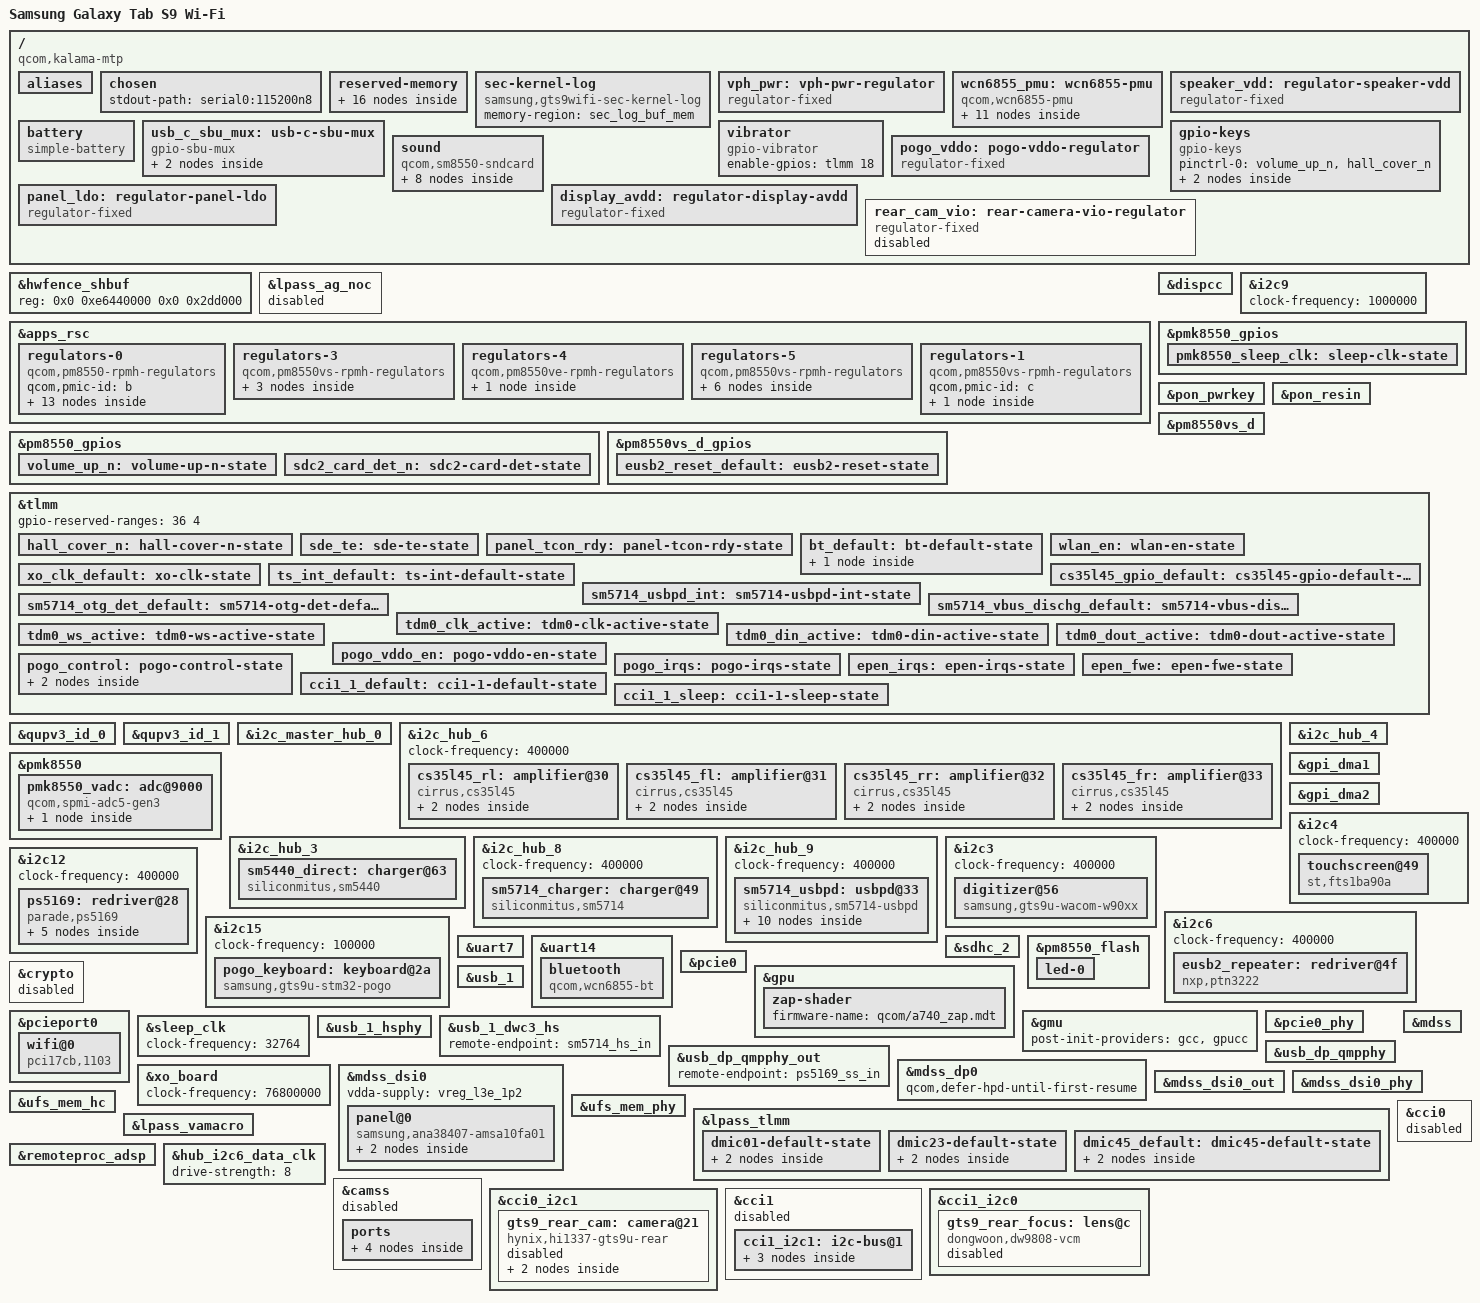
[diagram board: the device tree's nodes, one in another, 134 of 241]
// SPDX-License-Identifier: BSD-3-Clause
/*
 * Initial mainline device tree for the Samsung Galaxy Tab S9 Ultra Wi-Fi
 * (SM-X710, gts9wifi).  Derived from the validated gts9uwifi board; the
 * family shares the SoC, bus topology, amplifiers, charging and pen stack.
 * X710 deltas: AMSA10FA01 panel glass, STM FTS touch (Goodix on some units),
 * WCN6855/QCA6490 WLAN+BT, two HI1337 cameras (described at the end of this
 * file and disabled at boot; gts9wifi_camera enables them on request).
 *
 * Only hardware evidenced by the live downstream tree is enabled here.
 * Native display support remains disabled; Samsung ABL's preserved splash
 * framebuffer is used for the first visual milestone.
 */

/dts-v1/;

#include <dt-bindings/gpio/gpio.h>
#include <dt-bindings/input/input.h>
#include <dt-bindings/iio/qcom,spmi-vadc.h>
#include <dt-bindings/interrupt-controller/irq.h>
#include <dt-bindings/leds/common.h>
#include <dt-bindings/pinctrl/qcom,pmic-gpio.h>
#include <dt-bindings/regulator/qcom,rpmh-regulator.h>
#include <dt-bindings/usb/pd.h>
#include "sm8550.dtsi"
#include "pm8550.dtsi"
#include "pm8550vs.dtsi"
#include "pmk8550.dtsi"

/* Samsung's ADSP/SLPI carveout is larger than the SM8550 reference value. */
/delete-node/ &adspslpi_mem;

/ {
	model = "Samsung Galaxy Tab S9 Wi-Fi";
	/*
	 * The first three strings and the legacy IDs are consumed by Samsung ABL
	 * when it selects the base DTB.  Keep the upstream compatibles as well so
	 * Linux still identifies the actual board and SoC normally.
	 */
	compatible = "qcom,kalama-mtp", "qcom,kalama", "qcom,mtp",
		     "samsung,gts9wifi", "qcom,sm8550";
	qcom,msm-id = <0x218 0x20000 0x207 0x20000
		       0x207 0x10000 0x218 0x10000>;
	/*
	 * Samsung's gts9wifi_eur_open_w00_r04.dts: board-id 04 covers hw_rev 4..0x20;
	 * this unit is rev 6.  The Ultra's trees carry 03.
	 */
	qcom,board-id = <0x10008 0x04>;
	chassis-type = "tablet";

	aliases {
		serial0 = &uart7;
		mmc1 = &sdhc_2;
	};

	chosen {
		stdout-path = "serial0:115200n8";
		/*
		 * The simple-framebuffer is intentionally gone: the native msm
		 * DPU + DSI pipeline (below) owns the panel now.  If the panel
		 * bring-up regresses, recover over SSH (Wi-Fi) or reflash v0.53.
		 */
	};

	reserved-memory {
		/*
		 * Samsung ABL patches the /memory ranges but, without the stock
		 * overlay, does not add the board-only protected carveouts below.
		 * Keep them out of the buddy allocator: touching one of these ranges
		 * can make the secure firmware reset the SoC with a fatal NoC error.
		 */
		kaslr_mem: kaslr@b01ff000 {
			reg = <0x0 0xb01ff000 0x0 0x1000>;
			no-map;
		};

		uh_heap_mem: uh-heap@b0200000 {
			reg = <0x0 0xb0200000 0x0 0x40000>;
			no-map;
		};

		uh_guest_mem: uh-guest@b1000000 {
			reg = <0x0 0xb1000000 0x0 0x3a00000>;
			no-map;
		};

		chipinfo_mem: chipinfo@81cf4000 {
			reg = <0x0 0x81cf4000 0x0 0x1000>;
			no-map;
		};

		sec_xbl_ramdump_mem: sec-xbl-ramdump@a7d00000 {
			reg = <0x0 0xa7d00000 0x0 0x300000>;
			no-map;
		};

		adspslpi_mem: adspslpi@9ea00000 {
			reg = <0x0 0x9ea00000 0x0 0x59b4000>;
			no-map;
		};

		llcc_lpi_mem: llcc-lpi@ff800000 {
			reg = <0x0 0xff800000 0x0 0x600000>;
			no-map;
		};

		/* X910 ABL expects this exact downstream node name and label. */
		splash_region {
			reg = <0x0 0xb8000000 0x0 0x2b00000>;
			label = "cont_splash_region";
			no-map;
		};

		sec_debug_pool_mem: sec-debug-pool@880100000 {
			reg = <0x8 0x80100000 0x0 0xff000>;
			no-map;
		};

		sec_reset_info_mem: sec-reset-info@8801ff000 {
			reg = <0x8 0x801ff000 0x0 0x1000>;
			no-map;
		};

		/* Shared with Samsung bootloader and recovery for /proc/last_kmsg. */
		sec_log_buf_mem: sec-log@880200000 {
			reg = <0x8 0x80200000 0x0 0x200000>;
		};

		sec_debug_bl_mem: sec-debug-bl@880400000 {
			reg = <0x8 0x80400000 0x0 0x500000>;
			no-map;
		};

		/*
		 * Samsung's own kernel keeps its pstore pmsg log in this carve-out
		 * (samsung,pstore_pmsg in the stock gts9wifi overlay) so that it
		 * survives a reset.  Nothing else uses it here: make it the ramoops
		 * backend.  The previous boot's console and its oops/panic records
		 * then appear under /sys/fs/pstore, even when the hang left no
		 * journal.  Write-combined (mem-type 0), so writes reach DDR before
		 * a reset; ECC flags a record the reset corrupted.
		 *
		 * Checked on the X710 (2026-11-07): the console record survived
		 * every warm reboot and watchdog reset, and nothing suggests the
		 * bootloader overruns sec-debug-bl (which ends exactly here) into
		 * it: zone 0 (the first dmesg record) read back uncorrectable only
		 * on the two boots that followed a TWRP session, consistent with
		 * Samsung's kernel there writing its sec_pmsg ring from offset 0.
		 * The console zone is the second MiB and was intact even then.
		 * The few corrected header bytes reported in six of the eight
		 * dmesg zones at every boot first appeared across one clean reboot
		 * after Stage 1 had zapped every zone.  They persist because
		 * ramoops rewrites a dmesg zone's header only when it stores an
		 * oops or panic there, and they creep up a byte at a time (2 2 5 2
		 * 3 3 -> 3 2 5 2 3 4 over that night's five boot-loop boots):
		 * scattered bytes accumulating in untouched headers, not the
		 * contiguous overwrite from offset 0 an overrun would leave.  ECC
		 * corrects up to 8 bytes per header; a zone past that reads back
		 * uncorrectable and is normally zapped and rewritten.  No reason
		 * to move or shrink the region.  systemd-pstore's copies are kept
		 * per boot by ubuntu-gts9u-pstore-archive.service (the device
		 * package).
		 */
		sec_pmsg_mem: sec-pmsg@880900000 {
			compatible = "ramoops";
			reg = <0x8 0x80900000 0x0 0x200000>;
			no-map;
			record-size = <0x20000>;
			console-size = <0x100000>;
			ecc-size = <16>;
		};

		google_debug_kinfo_mem: google-debug-kinfo@880b00000 {
			reg = <0x8 0x80b00000 0x0 0x1000>;
			no-map;
		};

		hdm_mem: hdm@880b01000 {
			reg = <0x8 0x80b01000 0x0 0x1000>;
			no-map;
		};

		sec_qcom_rdx_mem: sec-qcom-rdx@880c00000 {
			reg = <0x8 0x80c00000 0x0 0xad00000>;
			no-map;
		};
	};

	sec-kernel-log {
		compatible = "samsung,gts9wifi-sec-kernel-log", "samsung,gts9uwifi-sec-kernel-log";
		memory-region = <&sec_log_buf_mem>;
	};

	/* Mainline WCN7850 power sequencer input, as on the SM8550 QRD. */
	vph_pwr: vph-pwr-regulator {
		compatible = "regulator-fixed";
		regulator-name = "vph_pwr";
		regulator-min-microvolt = <3700000>;
		regulator-max-microvolt = <3700000>;
		regulator-always-on;
		regulator-boot-on;
	};

	wcn6855_pmu: wcn6855-pmu {
		compatible = "qcom,wcn6855-pmu";
		pinctrl-names = "default";
		pinctrl-0 = <&wlan_en>, <&bt_default>, <&xo_clk_default>,
			    <&pmk8550_sleep_clk>;

		/*
		 * Stock gts9wifi cnss-qca6490 and bt_qca6490 nodes: wlan-en 80,
		 * bt-en 81, sw-ctrl 82 and xo-clk 204, the SM8450 HDK WCN6855
		 * wiring.  Unlike the X910's WCN7850 this part needs XO_CLK held
		 * high across BT_EN/WLAN_EN assertion; without it neither radio
		 * leaves reset (hci0 "Reading QCA version information failed
		 * (-110)", PCIe LTSSM parked in Detect, "Device not found").
		 */
		wlan-enable-gpios = <&tlmm 80 GPIO_ACTIVE_HIGH>;
		bt-enable-gpios = <&tlmm 81 GPIO_ACTIVE_HIGH>;
		swctrl-gpios = <&tlmm 82 GPIO_ACTIVE_HIGH>;
		xo-clk-gpios = <&tlmm 204 GPIO_ACTIVE_HIGH>;

		/*
		 * Stock cnss2 sends this exact qcom,pdc_init_table (gts9wifi r04
		 * qcom,cnss-qca6490 node) to the AOP through the QMP mailbox
		 * before the first WLAN power-on.  It programs the RF rail
		 * levels the AOP applies when the QCA6490 PMU raises its power
		 * requests over the PDC; without it the PMU handshake never
		 * completes on the X910 and both radios stay in reset.
		 */
		qcom,qmp = <&aoss_qmp>;
		qcom,wlan-pdc-init =
			"{class: wlan_pdc, ss: rf, res: s4e.v, upval: 966}",
			"{class: wlan_pdc, ss: rf, res: s4e.v, dwnval: 615}",
			"{class: wlan_pdc, ss: rf, res: s4g.v, upval: 1350}",
			"{class: wlan_pdc, ss: rf, res: s4g.v, dwnval: 945}",
			"{class: wlan_pdc, ss: rf, res: s6g.v, upval: 1900}",
			"{class: wlan_pdc, ss: rf, res: s6g.v, dwnval: 1825}",
			"{class: wlan_pdc, ss: rf, res: s2g.m, enable: 1}",
			"{class: wlan_pdc, ss: rf, res: s2g.v, enable: 1}",
			"{class: wlan_pdc, ss: rf, res: s2g.v, upval: 1012}",
			"{class: wlan_pdc, ss: rf, res: s2g.v, dwnval: 800}",
			"{class: wlan_pdc, ss: bb, res: pdc, enable: 0}";

		/*
		 * Rails as voted by the stock gts9wifi radio nodes: L15B io,
		 * S2G WLAN_AON (1.012 V), S4E dig/rfa0p8 (0.966 V), S4G 1.35 V
		 * and S6G 1.9 V, plus the S5G 0.966 V PMU core vote the Fedora
		 * and pmOS X710 trees carry (stock "vdd-wlan" has no phandle).
		 */
		vddio-supply = <&vreg_l15b_1p8>;
		vddaon-supply = <&vreg_s2g_1p012>;
		vddpmu-supply = <&vreg_s5g_0p968>;
		vddpmumx-supply = <&vreg_s5g_0p968>;
		vddpmucx-supply = <&vreg_s5g_0p968>;
		vddrfa0p95-supply = <&vreg_s4e_0p968>;
		vddrfa1p3-supply = <&vreg_s4g_1p352>;
		vddrfa1p9-supply = <&vreg_s6g_1p904>;
		vddpcie1p3-supply = <&vreg_s4g_1p352>;
		vddpcie1p9-supply = <&vreg_s6g_1p904>;

		regulators {
			vreg_pmu_rfa_cmn: ldo0 {
				regulator-name = "vreg_pmu_rfa_cmn_0p8";
			};

			vreg_pmu_aon_0p8: ldo1 {
				regulator-name = "vreg_pmu_aon_0p8";
			};

			vreg_pmu_wlcx_0p8: ldo2 {
				regulator-name = "vreg_pmu_wlcx_0p8";
			};

			vreg_pmu_wlmx_0p8: ldo3 {
				regulator-name = "vreg_pmu_wlmx_0p8";
			};

			vreg_pmu_btcmx_0p8: ldo4 {
				regulator-name = "vreg_pmu_btcmx_0p8";
			};

			vreg_pmu_pcie_1p8: ldo5 {
				regulator-name = "vreg_pmu_pcie_1p8";
			};

			vreg_pmu_pcie_0p9: ldo6 {
				regulator-name = "vreg_pmu_pcie_0p9";
			};

			vreg_pmu_rfa_0p8: ldo7 {
				regulator-name = "vreg_pmu_rfa_0p8";
			};

			vreg_pmu_rfa_1p2: ldo8 {
				regulator-name = "vreg_pmu_rfa_1p2";
			};

			vreg_pmu_rfa_1p7: ldo9 {
				regulator-name = "vreg_pmu_rfa_1p7";
			};
		};
	};

	/*
	 * The four CS35L45 speaker amplifiers share one board power switch.
	 * Samsung's stock overlay calls this a dummy regulator, but GPIO19 is
	 * the real active-high enable and the rail is intentionally always on.
	 */
	speaker_vdd: regulator-speaker-vdd {
		compatible = "regulator-fixed";
		regulator-name = "speaker_vdd";
		gpio = <&tlmm 19 GPIO_ACTIVE_HIGH>;
		enable-active-high;
		regulator-always-on;
		regulator-boot-on;
	};

	/*
	 * EB-BX916ABY.  The design figures come from Samsung's own sec-battery
	 * node (battery,battery_full_capacity = 9800 mAh, chg_float_voltage =
	 * 4440 mV), not from the marketing "11200 mAh" figure.  The fuel gauge
	 * reports state of charge itself, so these only feed the time-remaining
	 * estimate.
	 */
	battery: battery {
		compatible = "simple-battery";
		charge-full-design-microamp-hours = <9800000>;
		voltage-max-design-microvolt = <4440000>;
		voltage-min-design-microvolt = <3400000>;
	};

	/*
	 * The stock DP driver drives these two discrete AUX-path controls:
	 * GPIO183 is active-low enable and GPIO180 follows cable orientation.
	 * The generic mainline SBU mux maps those exact semantics onto Type-C.
	 */
	usb_c_sbu_mux: usb-c-sbu-mux {
		compatible = "gpio-sbu-mux";
		enable-gpios = <&tlmm 183 GPIO_ACTIVE_LOW>;
		select-gpios = <&tlmm 180 GPIO_ACTIVE_HIGH>;
		mode-switch;
		orientation-switch;

		port {
			usb_c_sbu_mux_in: endpoint {
				remote-endpoint = <&sm5714_sbu_out>;
			};
		};
	};

	/*
	 * Stock dc_vibrator: Samsung drives the coin motor from TLMM GPIO18.  The
	 * r04 overlay wires it exactly as the Ultra's does -- COINDC, gpio_en
	 * TLMM 18 active high (their "mot_ldo_en"), no regulator -- so the
	 * Ultra's node applies unchanged.  Tab Companion's keyboard and
	 * notification haptics find it by its input name, gpio-vibrator.
	 */
	vibrator {
		compatible = "gpio-vibrator";
		enable-gpios = <&tlmm 18 GPIO_ACTIVE_HIGH>;
	};

	gpio-keys {
		compatible = "gpio-keys";
		pinctrl-names = "default";
		pinctrl-0 = <&volume_up_n>, <&hall_cover_n>;

		key-volume-up {
			label = "Volume Up";
			linux,code = <KEY_VOLUMEUP>;
			gpios = <&pm8550_gpios 6 GPIO_ACTIVE_LOW>;
			debounce-interval = <15>;
			linux,can-disable;
			wakeup-source;
		};

		/*
		 * Samsung's stock hall_ic node identifies the book-cover magnet
		 * on TLMM GPIO107, active low, with a 50 ms debounce.  Report the
		 * standard SW_LID event so logind and GNOME can blank/suspend on
		 * close without a device-specific daemon.
		 */
		switch-lid {
			label = "Book Cover";
			linux,input-type = <EV_SW>;
			linux,code = <SW_LID>;
			gpios = <&tlmm 107 GPIO_ACTIVE_LOW>;
			debounce-interval = <50>;
			wakeup-source;
		};
	};

	/*
	 * Unlike the SM8550 QRD, the X710 has no WSA884x speaker path and no
	 * WCD938x. Its four CS35L45 amplifiers consume PRIMARY_MI2S_RX over
	 * TLMM126..129. Keep the first card deliberately small: one playback
	 * backend plus the native VA-macro DMIC capture backend.
	 */
	sound {
		compatible = "qcom,sm8550-sndcard", "qcom,sm8450-sndcard";
		model = "Samsung-Galaxy-Tab-S9";
		pinctrl-names = "default";
		pinctrl-0 = <&tdm0_clk_active>, <&tdm0_ws_active>,
			    <&tdm0_din_active>, <&tdm0_dout_active>;

		speaker-playback-dai-link {
			link-name = "CS35L45 Speaker Playback";

			cpu {
				sound-dai = <&q6apmbedai PRIMARY_MI2S_RX>;
			};

			codec {
				sound-dai = <&cs35l45_fl 0>, <&cs35l45_fr 0>,
					    <&cs35l45_rl 0>, <&cs35l45_rr 0>;
			};

			platform {
				sound-dai = <&q6apm>;
			};
		};

		va-capture-dai-link {
			link-name = "Internal DMIC Capture";

			cpu {
				/*
				 * The VA macro has its own LPASS DMA lane: its
				 * capture lands on VA_CODEC_DMA_TX_0, not on the
				 * TX macro's TX_CODEC_DMA_TX_3 (which is where
				 * the reference boards take their soundwire mics
				 * from, and which this tablet does not have).
				 * Wiring the link to the TX lane leaves the
				 * backend with no data and arecord fails with
				 * -EIO.
				 */
				sound-dai = <&q6apmbedai VA_CODEC_DMA_TX_0>;
			};

			codec {
				sound-dai = <&lpass_vamacro 0>;
			};

			platform {
				sound-dai = <&q6apm>;
			};
		};
	};
};

/* The X910 firmware reserves a slightly larger HW-fence window than MTP. */
&hwfence_shbuf {
	reg = <0x0 0xe6440000 0x0 0x2dd000>;
};

/*
 * The v0.5 video ends after the two preceding LPASS NOC providers probe and
 * before this provider can return.  Audio is out of scope for milestone 1;
 * keep the unsafe access quiescent until its board-specific power sequence is
 * understood.
 */
&lpass_ag_noc {
	status = "disabled";
};

&apps_rsc {
	/* PM8550B: only the two external-SD rails needed for milestone 1. */
	regulators-0 {
		compatible = "qcom,pm8550-rpmh-regulators";
		qcom,pmic-id = "b";

		/*
		 * Sensor VDD. Samsung's remoteproc-adsp node votes PM8550B L1 at
		 * 1.8 V as sensor_vdd while the sensors protection domain runs.
		 * Mainline qcom_q6v5_pas only manages cx/px supplies, so keep the
		 * exact stock rail enabled until generic auxiliary-supply handling
		 * exists in that driver. On the X910, omitting both sensor rails
		 * correlates with the sensors PD watchdog during SSC bring-up.
		 */
		vreg_l1b_1p8: ldo1 {
			regulator-name = "vreg_l1b_1p8";
			regulator-min-microvolt = <1800000>;
			regulator-max-microvolt = <1800000>;
			regulator-initial-mode = <RPMH_REGULATOR_MODE_HPM>;
			regulator-always-on;
		};

		/* NXP PTN3222 eUSB2 3.1 V rail, exact X910 stock voltage. */
		vreg_l5b_3p104: ldo5 {
			regulator-name = "vreg_l5b_3p104";
			regulator-min-microvolt = <3104000>;
			regulator-max-microvolt = <3104000>;
			regulator-initial-mode = <RPMH_REGULATOR_MODE_HPM>;
			regulator-allow-set-load;
			regulator-allowed-modes = <RPMH_REGULATOR_MODE_LPM
						   RPMH_REGULATOR_MODE_HPM>;
		};

		vreg_l8b_1p8: ldo8 {
			regulator-name = "vreg_l8b_1p8";
			regulator-min-microvolt = <1800000>;
			regulator-max-microvolt = <3000000>;
			regulator-initial-mode = <RPMH_REGULATOR_MODE_HPM>;
		};

		vreg_l9b_2p9: ldo9 {
			regulator-name = "vreg_l9b_2p9";
			regulator-min-microvolt = <2960000>;
			regulator-max-microvolt = <3000000>;
			regulator-initial-mode = <RPMH_REGULATOR_MODE_HPM>;
		};

		/*
		 * Digital microphone bias.  Samsung wires the VA macro's
		 * va-vdd-micb to this LDO (their pm_humu_l10, resource ldob10) at
		 * 1.8 V; without it the driver falls back to a dummy regulator and
		 * the DMICs stay unpowered, so capture returns silence.
		 */
		vreg_l10b_1p8: ldo10 {
			regulator-name = "vreg_l10b_1p8";
			regulator-min-microvolt = <1800000>;
			regulator-max-microvolt = <1800000>;
			regulator-initial-mode = <RPMH_REGULATOR_MODE_HPM>;
			/*
			 * The VA macro declares vdd-micb as a DAPM regulator
			 * supply but never puts it in a route, so the widget is
			 * never powered and the rail stays off even with a
			 * capture running - the microphones then sit unpowered
			 * and return digital silence.  Until the driver wires
			 * that supply into the DMIC paths, keep the rail up.
			 */
			regulator-always-on;
		};

		/* Stock pm_humu_l11: shared 1.1 V camera/display digital rail. */
		vreg_l11b_1p2: ldo11 {
			regulator-name = "vreg_l11b_1p2";
			/*
			 * Panel VDD.  The gts9wifi stock tree leaves L11B at its
			 * 1.200 V base vote (the X910 overlay lowers it to 1.100 V) and
			 * the pmOS tree drives this glass at 1.2 V as well.
			 */
			regulator-min-microvolt = <1200000>;
			regulator-max-microvolt = <1200000>;
			regulator-initial-mode = <RPMH_REGULATOR_MODE_HPM>;
		};

		vreg_l12b_1p8: ldo12 {
			regulator-name = "vreg_l12b_1p8";
			regulator-min-microvolt = <1800000>;
			regulator-max-microvolt = <1800000>;
			regulator-initial-mode = <RPMH_REGULATOR_MODE_HPM>;
		};

		/* Display panel VCI (3.0 V analog). */
		vreg_l13b_3p0: ldo13 {
			regulator-name = "vreg_l13b_3p0";
			regulator-min-microvolt = <3000000>;
			regulator-max-microvolt = <3000000>;
			regulator-initial-mode = <RPMH_REGULATOR_MODE_HPM>;
		};

		vreg_l14b_3p2: ldo14 {
			regulator-name = "vreg_l14b_3p2";
			regulator-min-microvolt = <3200000>;
			regulator-max-microvolt = <3200000>;
			regulator-initial-mode = <RPMH_REGULATOR_MODE_HPM>;
		};

		/* NXP PTN3222 eUSB2 1.8 V rail. */
		vreg_l15b_1p8: ldo15 {
			regulator-name = "vreg_l15b_1p8";
			regulator-min-microvolt = <1800000>;
			regulator-max-microvolt = <1800000>;
			regulator-initial-mode = <RPMH_REGULATOR_MODE_HPM>;
			regulator-allow-set-load;
			regulator-allowed-modes = <RPMH_REGULATOR_MODE_LPM
						   RPMH_REGULATOR_MODE_HPM>;
		};

		/*
		 * Sensor VDDIO. The stock ADSP node requests PM8550B L16 at
		 * 3.0 V (sensor_vddio-uV-uA = <3000000 0>); see L1 above for why
		 * this is temporarily an always-on board rail.
		 */
		vreg_l16b_3p0: ldo16 {
			regulator-name = "vreg_l16b_3p0";
			regulator-min-microvolt = <3000000>;
			regulator-max-microvolt = <3000000>;
			regulator-initial-mode = <RPMH_REGULATOR_MODE_HPM>;
			regulator-always-on;
		};

		/* Internal UFS VCC (memory core). */
		vreg_l17b_2p5: ldo17 {
			regulator-name = "vreg_l17b_2p5";
			regulator-min-microvolt = <2504000>;
			regulator-max-microvolt = <2504000>;
			regulator-initial-mode = <RPMH_REGULATOR_MODE_HPM>;
			regulator-allow-set-load;
			regulator-allowed-modes = <RPMH_REGULATOR_MODE_LPM
						   RPMH_REGULATOR_MODE_HPM>;
		};
	};

	/* PM8550VS-E: rails consumed by the primary USB2 PHY. */
	regulators-3 {
		compatible = "qcom,pm8550vs-rpmh-regulators";
		qcom,pmic-id = "e";
		vdd-s4-supply = <&vph_pwr>;
		vdd-s5-supply = <&vph_pwr>;

		vreg_s4e_0p968: smps4 {
			regulator-name = "vreg_s4e_0p968";
			/*
			 * The stock gts9wifi bt/cnss nodes vote 0.966 V here (the
			 * X910 asks 0.950 V); FTSMPS525 rounds up in 4 mV steps.
			 */
			regulator-min-microvolt = <968000>;
			regulator-max-microvolt = <968000>;
			regulator-initial-mode = <RPMH_REGULATOR_MODE_HPM>;
		};

		vreg_l1e_0p88: ldo1 {
			regulator-name = "vreg_l1e_0p88";
			regulator-min-microvolt = <880000>;
			regulator-max-microvolt = <880000>;
			regulator-initial-mode = <RPMH_REGULATOR_MODE_HPM>;
		};

		vreg_l3e_1p2: ldo3 {
			regulator-name = "vreg_l3e_1p2";
			regulator-min-microvolt = <1200000>;
			regulator-max-microvolt = <1200000>;
			regulator-initial-mode = <RPMH_REGULATOR_MODE_HPM>;
		};
	};

	/* PM8550VE-F: 0.88 V PLL rail for the USB3/DisplayPort combo PHY. */
	regulators-4 {
		compatible = "qcom,pm8550ve-rpmh-regulators";
		qcom,pmic-id = "f";
		vdd-l1-supply = <&vreg_s4e_0p968>;
		vdd-l2-supply = <&vreg_s4e_0p968>;
		vdd-l3-supply = <&vreg_s4e_0p968>;

		vreg_l3f_0p88: ldo3 {
			regulator-name = "vreg_l3f_0p88";
			regulator-min-microvolt = <880000>;
			regulator-max-microvolt = <912000>;
			regulator-initial-mode = <RPMH_REGULATOR_MODE_HPM>;
		};
	};

	/* PM8550VS-G supplies the discrete WCN7850/Kiwi v2 radio PMU. */
	regulators-5 {
		compatible = "qcom,pm8550vs-rpmh-regulators";
		qcom,pmic-id = "g";
		vdd-s1-supply = <&vph_pwr>;
		vdd-s2-supply = <&vph_pwr>;
		vdd-s3-supply = <&vph_pwr>;
		vdd-s4-supply = <&vph_pwr>;
		vdd-s5-supply = <&vph_pwr>;
		vdd-s6-supply = <&vph_pwr>;

		vreg_s2g_1p012: smps2 {
			regulator-name = "vreg_s2g_1p012";
			/* Stock gts9wifi cnss-qca6490 votes 1.012 V for WLAN_AON. */
			regulator-min-microvolt = <1012000>;
			regulator-max-microvolt = <1012000>;
			regulator-initial-mode = <RPMH_REGULATOR_MODE_HPM>;
		};

		vreg_s4g_1p352: smps4 {
			regulator-name = "vreg_s4g_1p352";
			/* Stock asks 1.350 V; FTSMPS525 rounds up in 4 mV steps. */
			regulator-min-microvolt = <1352000>;
			regulator-max-microvolt = <1352000>;
			regulator-initial-mode = <RPMH_REGULATOR_MODE_HPM>;
		};

		vreg_s5g_0p968: smps5 {
			regulator-name = "vreg_s5g_0p968";
			/*
			 * The stock gts9wifi cnss node lists a 0.966 V "vdd-wlan" rail
			 * without an APPS phandle; the Fedora and pmOS X710 trees feed
			 * the PMU core inputs from S5G at this level and bring the
			 * radios up, so keep that vote (FTSMPS525 4 mV steps).
			 */
			regulator-min-microvolt = <968000>;
			regulator-max-microvolt = <968000>;
			regulator-initial-mode = <RPMH_REGULATOR_MODE_HPM>;
		};

		vreg_s6g_1p904: smps6 {
			regulator-name = "vreg_s6g_1p904";
			/* Stock asks 1.900 V; FTSMPS525 rounds up in 8 mV steps. */
			regulator-min-microvolt = <1904000>;
			regulator-max-microvolt = <1904000>;
			regulator-initial-mode = <RPMH_REGULATOR_MODE_HPM>;
		};

		/*
		 * Do not add vdd-l3-supply here.  Mainline SM8550 boards expose
		 * PM8550VS-G LDO3 directly, and the experimental S4G parent used in
		 * v0.20 created a fixed dependency cycle with this provider.
		 */
		vreg_l3g_1p2: ldo3 {
			regulator-name = "vreg_l3g_1p2";
			regulator-min-microvolt = <1200000>;
			regulator-max-microvolt = <1200000>;
			regulator-initial-mode = <RPMH_REGULATOR_MODE_HPM>;
		};

		/* Internal UFS VCCQ (controller I/O). */
		vreg_l1g_1p2: ldo1 {
			regulator-name = "vreg_l1g_1p2";
			regulator-min-microvolt = <1200000>;
			regulator-max-microvolt = <1200000>;
			regulator-initial-mode = <RPMH_REGULATOR_MODE_HPM>;
			regulator-allow-set-load;
			regulator-allowed-modes = <RPMH_REGULATOR_MODE_LPM
						   RPMH_REGULATOR_MODE_HPM>;
		};
	};
};

&dispcc {
	/* Needed for the native display pipeline (mdss/dpu/dsi clocks). */
	status = "okay";
};

&pm8550_gpios {
	volume_up_n: volume-up-n-state {
		pins = "gpio6";
		function = "normal";
		power-source = <1>;
		bias-pull-up;
		input-enable;
	};

	sdc2_card_det_n: sdc2-card-det-state {
		pins = "gpio12";
		function = "normal";
		input-enable;
		output-disable;
		bias-pull-up;
		power-source = <1>; /* 1.8 V */
	};
};

&i2c9 {
	clock-frequency = <1000000>;
	status = "okay";

};

&pmk8550_gpios {
	pmk8550_sleep_clk: sleep-clk-state {
		pins = "gpio3";
		function = "func1";
		input-disable;
		output-enable;
		bias-disable;
		power-source = <0>;
	};
};

&pon_pwrkey {
	status = "okay";
};

&pon_resin {
	linux,code = <KEY_VOLUMEDOWN>;
	/*
	 * Volume Down wakes the tablet like Volume Up and the power key, as
	 * under Android: Samsung's pm8941-pwrkey arms both PMIC keys and its
	 * init writes volkey_wakeup=1.  Mainline leaves resin unarmed.
	 */
	wakeup-source;
	status = "okay";
};

/* Stock X910 connects the NXP repeater reset to PM8550VS-D GPIO4. */
&pm8550vs_d {
	status = "okay";
};

&pm8550vs_d_gpios {
	eusb2_reset_default: eusb2-reset-state {
		pins = "gpio4";
		function = "normal";
		power-source = <1>;
		input-enable;
		output-enable;
		drive-push-pull;
		qcom,drive-strength = <PMIC_GPIO_STRENGTH_MED>;
		bias-disable;
	};
};

&tlmm {
	/* GPIO36..39 are secure/reserved in Samsung's board overlay. */
	gpio-reserved-ranges = <36 4>;

	hall_cover_n: hall-cover-n-state {
		pins = "gpio107";
		function = "gpio";
		drive-strength = <2>;
		input-enable;
		bias-disable;
	};

	/* Panel tear-effect (TE) line routed to the MDP vsync input. */
	sde_te: sde-te-state {
		pins = "gpio86";
		function = "mdp_vsync";
		drive-strength = <2>;
		bias-pull-down;
	};

	/* DDIC TCON_RDY input, as the stock panel_fa01_tcon_rdy_active state. */
	panel_tcon_rdy: panel-tcon-rdy-state {
		pins = "gpio88";
		function = "gpio";
		drive-strength = <2>;
		input-enable;
		bias-disable;
	};

	bt_default: bt-default-state {
		bt-en-pins {
			pins = "gpio81";
			function = "gpio";
			drive-strength = <16>;
			bias-disable;
		};
	};

	wlan_en: wlan-en-state {
		pins = "gpio80";
		function = "gpio";
		drive-strength = <16>;
		bias-pull-up;
	};

	/* WCN6855 XO_CLK: driven high by the PMU sequencer during power-on. */
	xo_clk_default: xo-clk-state {
		pins = "gpio204";
		function = "gpio";
		drive-strength = <16>;
		output-low;
		bias-pull-down;
	};

	/* FTS1BA90A attention line, as the stock fts1ba90a_attn_irq state. */
	ts_int_default: ts-int-default-state {
		pins = "gpio25";
		function = "gpio";
		bias-disable;
	};

	cs35l45_gpio_default: cs35l45-gpio-default-state {
		pins = "gpio14", "gpio42";
		function = "gpio";
		drive-strength = <2>;
		bias-disable;
	};

	sm5714_usbpd_int: sm5714-usbpd-int-state {
		pins = "gpio133";
		function = "gpio";
		drive-strength = <8>;
		input-enable;
		bias-disable;
	};

	sm5714_otg_det_default: sm5714-otg-det-default-state {
		pins = "gpio89";
		function = "gpio";
		drive-strength = <2>;
		output-low;
		bias-disable;
	};

	sm5714_vbus_dischg_default: sm5714-vbus-dischg-default-state {
		pins = "gpio175";
		function = "gpio";
		drive-strength = <2>;
		output-low;
		bias-pull-down;
	};

	tdm0_clk_active: tdm0-clk-active-state {
		pins = "gpio126";
		function = "i2s0_sck";
		drive-strength = <2>;
		bias-disable;
		output-high;
	};

	tdm0_ws_active: tdm0-ws-active-state {
		pins = "gpio129";
		function = "i2s0_ws";
		drive-strength = <2>;
		bias-disable;
		output-high;
	};

	tdm0_din_active: tdm0-din-active-state {
		pins = "gpio127";
		function = "i2s0_data0";
		drive-strength = <2>;
		bias-disable;
	};

	tdm0_dout_active: tdm0-dout-active-state {
		pins = "gpio128";
		function = "i2s0_data1";
		drive-strength = <2>;
		bias-disable;
	};

	pogo_vddo_en: pogo-vddo-en-state {
		pins = "gpio10";
		function = "gpio";
		drive-strength = <2>;
		output-low;
		bias-disable;
	};

	pogo_control: pogo-control-state {
		boot-pins {
			pins = "gpio12";
			function = "gpio";
			drive-strength = <2>;
			output-low;
			bias-disable;
		};

		reset-pins {
			pins = "gpio13";
			function = "gpio";
			drive-strength = <2>;
			output-high;
			bias-disable;
		};
	};

	pogo_irqs: pogo-irqs-state {
		pins = "gpio62", "gpio75";
		function = "gpio";
		drive-strength = <2>;
		input-enable;
		bias-disable;
	};

	/*
	 * S Pen digitiser interrupt lines, as Samsung's r04 epen-int-active and
	 * epen-pdct-active states (and the Ultra's node): gpio154 is the data
	 * interrupt, gpio137 the pen-in-silo detect.  Both are inputs with the
	 * pull disabled.
	 */
	epen_irqs: epen-irqs-state {
		pins = "gpio154", "gpio137";
		function = "gpio";
		drive-strength = <2>;
		input-enable;
		bias-disable;
	};

	/*
	 * The digitiser's flash enable.  High across a power-up starts the
	 * controller's loader (Samsung's boot_addr, 0x09) instead of the
	 * digitiser at 0x56.  Samsung's probe drives it low and keeps it there
	 * (wacom_compulsory_flash_mode(false) in wacom_i2c.c); only its firmware
	 * flasher ever raises it, and this port has none.  Hold it low rather
	 * than leave it at whatever the reset default or ABL left behind.
	 */
	epen_fwe: epen-fwe-state {
		pins = "gpio179";
		function = "gpio";
		drive-strength = <2>;
		output-low;
		bias-disable;
	};
};

&qupv3_id_0 {
	status = "okay";
};

/* UART14 (WCN7850 Bluetooth) is a child of the second QUPv3 wrapper. */
&qupv3_id_1 {
	status = "okay";
};

/*
 * Samsung numbers this I2C18. On mainline it is SE6 of the dedicated QUPv3
 * I2C master hub (0x998000), and all four speaker amplifiers live here.
 */
&i2c_master_hub_0 {
	status = "okay";
};

&i2c_hub_6 {
	/*
	 * 400 kHz, not the 1 MHz the downstream stack uses.  Under mainline the
	 * QUPv3 i2c-master-hub runs its SEs in FIFO/PIO mode (no GPI DMA), and at
	 * 1 MHz Fast-Mode Plus the SE accepts the M_CMD but never drives the bus
	 * (mid-hang: bus idle, both lines high, zero interrupts) - the QUP core
	 * clock available to PIO is not enough for FM+.  Every upstream SM8550
	 * board that puts real devices on the i2c hub runs it at <=400 kHz
	 * (sm8550-hdk/mtp/qrd typec muxes at default, sony-xperia-yodo at 400 kHz);
	 * none run it at 1 MHz.  400 kHz is ample for CS35L45 register access and
	 * DSP firmware download.
	 */
	clock-frequency = <400000>;
	status = "okay";

	cs35l45_rl: amplifier@30 {
		compatible = "cirrus,cs35l45";
		reg = <0x30>;
		#sound-dai-cells = <1>;
		interrupt-parent = <&tlmm>;
		interrupts = <14 IRQ_TYPE_LEVEL_LOW>;
		reset-gpios = <&tlmm 42 GPIO_ACTIVE_HIGH>;
		vdd-a-supply = <&speaker_vdd>;
		vdd-batt-supply = <&speaker_vdd>;
		pinctrl-names = "default";
		pinctrl-0 = <&cs35l45_gpio_default>;
		sound-name-prefix = "Rear Left";
		cirrus,asp-sdout-hiz-ctrl = <3>;

		cirrus,gpio-ctrl1 {
			gpio-ctrl = <2>;
		};

		cirrus,gpio-ctrl2 {
			gpio-ctrl = <2>;
		};
	};

	cs35l45_fl: amplifier@31 {
		compatible = "cirrus,cs35l45";
		reg = <0x31>;
		#sound-dai-cells = <1>;
		interrupt-parent = <&tlmm>;
		interrupts = <14 IRQ_TYPE_LEVEL_LOW>;
		reset-gpios = <&tlmm 42 GPIO_ACTIVE_HIGH>;
		vdd-a-supply = <&speaker_vdd>;
		vdd-batt-supply = <&speaker_vdd>;
		pinctrl-names = "default";
		pinctrl-0 = <&cs35l45_gpio_default>;
		sound-name-prefix = "Front Left";
		cirrus,asp-sdout-hiz-ctrl = <3>;

		cirrus,gpio-ctrl1 {
			gpio-ctrl = <2>;
		};

		cirrus,gpio-ctrl2 {
			gpio-ctrl = <2>;
		};
	};

	cs35l45_rr: amplifier@32 {
		compatible = "cirrus,cs35l45";
		reg = <0x32>;
		#sound-dai-cells = <1>;
		interrupt-parent = <&tlmm>;
		interrupts = <14 IRQ_TYPE_LEVEL_LOW>;
		reset-gpios = <&tlmm 42 GPIO_ACTIVE_HIGH>;
		vdd-a-supply = <&speaker_vdd>;
		vdd-batt-supply = <&speaker_vdd>;
		pinctrl-names = "default";
		pinctrl-0 = <&cs35l45_gpio_default>;
		sound-name-prefix = "Rear Right";
		cirrus,asp-sdout-hiz-ctrl = <3>;

		cirrus,gpio-ctrl1 {
			gpio-ctrl = <2>;
		};

		cirrus,gpio-ctrl2 {
			gpio-ctrl = <2>;
		};
	};

	cs35l45_fr: amplifier@33 {
		compatible = "cirrus,cs35l45";
		reg = <0x33>;
		#sound-dai-cells = <1>;
		interrupt-parent = <&tlmm>;
		interrupts = <14 IRQ_TYPE_LEVEL_LOW>;
		reset-gpios = <&tlmm 42 GPIO_ACTIVE_HIGH>;
		vdd-a-supply = <&speaker_vdd>;
		vdd-batt-supply = <&speaker_vdd>;
		pinctrl-names = "default";
		pinctrl-0 = <&cs35l45_gpio_default>;
		sound-name-prefix = "Front Right";
		cirrus,asp-sdout-hiz-ctrl = <3>;

		cirrus,gpio-ctrl1 {
			gpio-ctrl = <2>;
		};

		cirrus,gpio-ctrl2 {
			gpio-ctrl = <2>;
		};
	};
};

/*
 * Samsung's battery safety input is the external pack thermistor, not the
 * SM5714 fuel-gauge die temperature.  The stock DT exposes it as PMK8550 ADC5
 * Gen3 virtual channel 0x144 (PM8550 SID 1, AMUX1 with 100 kOhm pull-up).
 */
&pmk8550 {
	pmk8550_vadc: adc@9000 {
		compatible = "qcom,spmi-adc5-gen3";
		reg = <0x9000>, <0x9100>;
		interrupts = <0x0 0x90 0x1 IRQ_TYPE_EDGE_RISING>,
			     <0x0 0x91 0x1 IRQ_TYPE_EDGE_RISING>;
		#address-cells = <1>;
		#size-cells = <0>;
		#io-channel-cells = <1>;
		#thermal-sensor-cells = <1>;

		channel@144 {
			reg = <0x144>;
			label = "battery-thermistor";
			qcom,pre-scaling = <1 1>;
			qcom,ratiometric;
			qcom,hw-settle-time = <200>;
			qcom,avg-samples = <4>;
		};
	};
};

/*
 * QUP hub SE3 is the dedicated bus for the SM5440 2:1 direct-charge pump at
 * 0x63.  This is also an SSC-visible hub: enabling the upstream controller in
 * its default FIFO/PIO mode resets the SE and makes the complete SSC registry
 * disappear.  Samsung drives this exact node through GPI DMA.  Match that
 * topology so transfers are submitted as GPI TREs rather than reprogramming
 * the shared serial engine from the AP.
 *
 * The SM5440 driver coordinates this pump with the SM5714 switching path and
 * requests PPS through Linux TCPM.
 */
&i2c_hub_3 {
	clock-frequency = <400000>;
	dmas = <&gpi_dma1 0 3 QCOM_GPI_I2C>,
	       <&gpi_dma1 1 3 QCOM_GPI_I2C>;
	dma-names = "tx", "rx";
	qcom,enable-gsi-dma;
	status = "okay";

	sm5440_direct: charger@63 {
		compatible = "siliconmitus,sm5440";
		reg = <0x63>;
		tcpm-power-supply = <&sm5714_usbpd>;
	};
};

/*
 * Samsung's keyboard buck-boost converter is on hub SE4, not on the STM32's
 * SE15 bus.  The stock driver writes CONFIG2=0x70 and CONFIG1=0x8e every time
 * the pogo logic rail is enabled.  Keep the device as an unbound I2C peer: the
 * board-specific STM32 driver owns the exact two-register power sequence.
 */
&i2c_hub_4 {
	clock-frequency = <400000>;
	dmas = <&gpi_dma1 0 4 QCOM_GPI_I2C>,
	       <&gpi_dma1 1 4 QCOM_GPI_I2C>;
	dma-names = "tx", "rx";
	qcom,enable-gsi-dma;
	status = "okay";

};

/*
 * SE8 of the same I2C master hub (0x9a0000).  The Silicon Mitus SM5714 combo
 * PMIC answers here on three addresses: charger at 0x49, fuel gauge at 0x71 and
 * MUIC at 0x25.  Its USB-PD block sits on the *next* SE instead (i2c_hub_9,
 * 0x9a4000, address 0x33 - confirmed with i2cdetect).  Keep the controller
 * enabled for the SM5714 TCPC driver, which leaves policy to Linux TCPM.
 *
 * Stock runs both at 400 kHz (qcom,clk-freq-out = <400000>), which is also the
 * only speed this hub reaches in PIO mode - see the note on i2c_hub_6.
 */
&i2c_hub_8 {
	clock-frequency = <400000>;
	status = "okay";

	/*
	 * SM8550 normally reports the battery over pmic_glink/qcom_battmgr, but
	 * that needs a charger_pd protection domain on the ADSP and Samsung's
	 * firmware ships none - only root_pd, sensor_pd, audio_pd and the CDSP
	 * root_pd.  The SM5714 is driven from the AP instead.
	 */
	sm5714_charger: charger@49 {
		compatible = "siliconmitus,sm5714";
		reg = <0x49>;
		io-channels = <&pmk8550_vadc 0x144>;
		io-channel-names = "battery-temp";
		monitored-battery = <&battery>;
	};
};

&i2c_hub_9 {
	clock-frequency = <400000>;
	status = "okay";

	sm5714_usbpd: usbpd@33 {
		compatible = "siliconmitus,sm5714-usbpd";
		reg = <0x33>;
		interrupts-extended = <&tlmm 133 IRQ_TYPE_LEVEL_LOW>;
		pinctrl-names = "default";
		pinctrl-0 = <&sm5714_usbpd_int &sm5714_otg_det_default
			     &sm5714_vbus_dischg_default>;
		otg-det-gpios = <&tlmm 89 GPIO_ACTIVE_HIGH>;
		wakeup-source;

		sm5714_connector: connector {
			compatible = "usb-c-connector";
			power-role = "dual";
			data-role = "dual";
			try-power-role = "sink";
			displayport = <&mdss_dp0>;

			/*
			 * Samsung limits the switching-charger PD path to
			 * 15 W and 9 V. PPS direct charging through SM5440
			 * raises the programmable APDO only after Q4 is open.
			 */
			op-sink-microwatt = <15000000>;
			sink-pdos = <PDO_FIXED(5000, 3000,
					       PDO_FIXED_DUAL_ROLE |
					       PDO_FIXED_DATA_SWAP |
					       PDO_FIXED_USB_COMM)
				     PDO_FIXED(9000, 1660,
					       PDO_FIXED_USB_COMM)>;
			source-pdos = <PDO_FIXED(5000, 900,
						 PDO_FIXED_DUAL_ROLE |
						 PDO_FIXED_DATA_SWAP |
						 PDO_FIXED_USB_COMM)>;

			/*
			 * The SM8550 QMP PHY and DPU expose a DisplayPort
			 * source.  Register the local Type-C alternate mode so
			 * TCPM can match the dock's 0xff01 partner mode and
			 * negotiate pin assignment C or D.
			 */
			altmodes {
				displayport {
					svid = /bits/ 16 <0xff01>;
					vdo = <0x00001c46>;
				};
			};

			ports {
				#address-cells = <1>;
				#size-cells = <0>;

				port@0 {
					reg = <0>;

					sm5714_hs_in: endpoint {
						remote-endpoint =
							<&usb_1_dwc3_hs>;
					};
				};

				port@1 {
					reg = <1>;

					sm5714_ss_in: endpoint {
						remote-endpoint =
							<&ps5169_ss_out>;
					};
				};

				port@2 {
					reg = <2>;

					sm5714_sbu_out: endpoint {
						remote-endpoint =
							<&usb_c_sbu_mux_in>;
					};
				};
			};
		};
	};
};

/* I2C4 (touch) and I2C6 (PTN3222) are GPI-only on SM8550. */
&gpi_dma1 {
	status = "okay";
};

/* QUP wrapper 2 / SE12 carries the board's PS5169 combo redriver. */
&gpi_dma2 {
	status = "okay";
};

/*
 * SE3 carries the Wacom EMR digitiser behind the S Pen.  Samsung's overlay puts
 * it at wacom@56 on qupv3_se3_i2c, which is this bus: their SE numbering and
 * mainline's i2cN agree, as the pogo controller on SE15 already showed.
 *
 * Neither mainline Wacom driver can drive it, so this port carries its own;
 * the reasons are in kernel/drivers/samsung_wacom_w90xx.c.
 *
 * Samsung's r04 node (fragment@81) is the Ultra's line for line: wacom,w90xx
 * at 0x56, IRQ TLMM154, pdct TLMM137, fwe TLMM179, AVDD pm_humu_l13,
 * boot_addr 9, origin 0 0, invert 0 0 0, table_swap 2, garage and cover
 * detection.  Only the firmware image (wez01_gts9.bin) and the sensor grid
 * (37 x 23 channels against 49 x 31) differ, and this driver loads no
 * firmware, so the Ultra's node carries over with this panel's size added.
 *
 * AVDD is LDO13 of PMIC B, shared with the panel's VCI.  The driver holds its
 * own reference because the display comes up long after this probe.  Samsung
 * pins that rail at 3.3 V for the digitiser while the panel's VCI entry asks
 * for 3.0 V; this tree keeps the panel's 3.0 V, which is what the Ultra's
 * digitiser has run on since its driver was written.
 *
 * pdct is the pen-in-silo detect: the driver reports it as SW_PEN_INSERTED,
 * starts the silo charging from it and, on this board, arms it for wake as
 * Samsung does, so drawing the pen or docking it wakes the tablet.  fwe only
 * matters to a firmware flasher, which this port does not have; its pin state
 * (epen_fwe) holds it low, as Samsung's probe does.
 *
 * The digitiser also reports the keyboard cover closing over the screen, as
 * SW_MACHINE_COVER and SW_LID.  That is a third lid switch on this board, next
 * to gpio-keys and the pogo keyboard, and logind acts on each of them.
 *
 * Orientation: the same properties as the touchscreen node.  Samsung gives
 * both tablets' digitisers the same origin and invert flags, the grid runs
 * portrait against the panel's landscape scanout as the touch controller's
 * does, and the Ultra's transform was measured with the pen on two opposite
 * corners in native landscape, where the compositor applies no rotation of
 * its own.  nacht20-de's X710 driver applies the same transform in code (x
 * from the controller's y, y from x_max - x).  The corner test still has to
 * confirm it on this unit.
 *
 * touchscreen-x-mm and -y-mm are the controller's own axes, before the swap:
 * the panel's short side first (236 x 148 mm, as the panel driver reports).
 * They set the resolution, from which libinput takes the pen's size and the
 * area around the tip in which it holds touch back.
 */
&i2c3 {
	clock-frequency = <400000>;
	status = "okay";

	digitizer@56 {
		compatible = "samsung,gts9u-wacom-w90xx";
		reg = <0x56>;
		avdd-supply = <&vreg_l13b_3p0>;
		pdct-gpios = <&tlmm 137 GPIO_ACTIVE_HIGH>;
		interrupts-extended = <&tlmm 154 IRQ_TYPE_LEVEL_LOW>;
		pinctrl-names = "default";
		pinctrl-0 = <&epen_irqs>, <&epen_fwe>;
		touchscreen-inverted-x;
		touchscreen-swapped-x-y;
		touchscreen-x-mm = <148>;
		touchscreen-y-mm = <236>;
	};
};

&i2c4 {
	clock-frequency = <400000>;
	status = "okay";

	/*
	 * STMicroelectronics FTS1BA90A (Samsung "FingerTip S"), verified on the
	 * test unit by TWRP's Samsung kernel binding fts_touch at 0x49.  The
	 * stock node is "stm,fts_touch", sec,max_coords <0x640 0xa00>
	 * (1600 x 2560), tsp_avdd_ldo = L14B 3.2 V, tsp_io_ldo = L12B 1.8 V,
	 * sec,irq_gpio = TLMM 25 (level low).  Mainline stmfts speaks a
	 * different FingerTipS command set and times out on this firmware;
	 * samsung_fts1ba90a.c (16-byte events, 0x60/0x61) drives it.  Other
	 * 11" units carry a Goodix GT9916 at 0x5d instead.
	 *
	 * The touch area is the panel's, 148 x 236 mm (stock r04) in the
	 * controller's portrait axes, which gives the input device its
	 * resolution.  wakeup-source: TLMM 25 is a PDC wake input (PDC 57);
	 * the driver arms it only while its double-tap gesture is armed in
	 * low-power mode, never with the controller powered off (the stock
	 * driver's enable_irq_wake() in fts_stop_device()).
	 */
	touchscreen@49 {
		compatible = "st,fts1ba90a";
		reg = <0x49>;
		interrupts-extended = <&tlmm 25 IRQ_TYPE_LEVEL_LOW>;
		pinctrl-names = "default";
		pinctrl-0 = <&ts_int_default>;
		avdd-supply = <&vreg_l14b_3p2>;
		vdd-supply = <&vreg_l12b_1p8>;
		touchscreen-size-x = <1600>;
		touchscreen-size-y = <2560>;
		touchscreen-x-mm = <148>;
		touchscreen-y-mm = <236>;
		touchscreen-inverted-x;
		touchscreen-swapped-x-y;
		wakeup-source;
	};

};

&i2c6 {
	clock-frequency = <400000>;
	status = "okay";

	eusb2_repeater: redriver@4f {
		compatible = "nxp,ptn3222";
		reg = <0x4f>;
		#phy-cells = <0>;

		vdd3v3-supply = <&vreg_l5b_3p104>;
		vdd1v8-supply = <&vreg_l15b_1p8>;
		reset-gpios = <&pm8550vs_d_gpios 4 GPIO_ACTIVE_LOW>;
		qcom,param-override-seq = <0x20 0x06 0x21 0x07
					   0x63 0x08 0x01 0x0a>;

		pinctrl-names = "default";
		pinctrl-0 = <&eusb2_reset_default>;
	};
};

&i2c12 {
	clock-frequency = <400000>;
	status = "okay";

	ps5169: redriver@28 {
		compatible = "parade,ps5169";
		reg = <0x28>;
		parade,reg50 = <0x10>;
		parade,reg51 = <0x70>;
		parade,reg54 = <0x02>;
		parade,reg5d = <0x40>;
		usb-role-switch = <&usb_1>;
		retimer-switch;
		orientation-switch;

		ports {
			#address-cells = <1>;
			#size-cells = <0>;

			port@0 {
				reg = <0>;

				ps5169_ss_out: endpoint {
					remote-endpoint = <&sm5714_ss_in>;
				};
			};

			port@1 {
				reg = <1>;

				ps5169_ss_in: endpoint {
					remote-endpoint =
						<&usb_dp_qmpphy_out>;
				};
			};
		};
	};
};

/*
 * Samsung's DTBO __fixups__ targets the pogo stm32@2a fragment at
 * qupv3_se15_i2c.  Mainline calls that controller i2c15; its standard pinctrl
 * already maps SDA/SCL to TLMM GPIO72/106.  The similarly named GPIO
 * properties in Samsung's child node are only used for diagnostics and MCU
 * recovery, not as a separate i2c-gpio bus.
 */
&i2c15 {
	/* Mainline GENI timing is more reliable with the STM32 at standard mode. */
	clock-frequency = <100000>;
	status = "okay";

	pogo_keyboard: keyboard@2a {
		compatible = "samsung,gts9u-stm32-pogo";
		reg = <0x2a>;
		vddo-supply = <&pogo_vddo>;
		boot-gpios = <&tlmm 12 GPIO_ACTIVE_HIGH>;
		reset-gpios = <&tlmm 13 GPIO_ACTIVE_LOW>;
		connected-gpios = <&tlmm 62 GPIO_ACTIVE_HIGH>;
		data-ready-gpios = <&tlmm 75 GPIO_ACTIVE_LOW>;
		/* No MAX77816 booster on the 11"; the driver treats it as optional. */
		pinctrl-names = "default";
		pinctrl-0 = <&pogo_control>, <&pogo_irqs>;
		wakeup-source;
	};
};

&uart7 {
	status = "okay";
};

/*
 * The Samsung downstream hsuart0 alias and pinctrl both identify QUP SE14
 * (0x898000) as the four-wire Bluetooth transport (WCN6855 on this board).  Power is shared
 * with Wi-Fi through the already-enabled wcn6855_pmu sequencer; keep the
 * upstream SM8550 QRD supply map so hci_qca can use that sequencer directly.
 */
&uart14 {
	status = "okay";

	bluetooth {
		compatible = "qcom,wcn6855-bt";
		/*
		 * No firmware-name on purpose.  For WCN6855 hci_qca derives
		 * hpbtfw21.tlv from the ROM version and hpnv21[g].bXX from the
		 * board id it reads back (falling back to hpnv21[g].bin), and
		 * those stems are exactly what Samsung ships for the X710; the
		 * Ultra had to pin hmtnv20.b21 only because its stock names do
		 * not match the driver's.  The overlay ships every variant.
		 */

		vddrfacmn-supply = <&vreg_pmu_rfa_cmn>;
		vddaon-supply = <&vreg_pmu_aon_0p8>;
		vddwlcx-supply = <&vreg_pmu_wlcx_0p8>;
		vddwlmx-supply = <&vreg_pmu_wlmx_0p8>;
		vddbtcmx-supply = <&vreg_pmu_btcmx_0p8>;
		vddrfa0p8-supply = <&vreg_pmu_rfa_0p8>;
		vddrfa1p2-supply = <&vreg_pmu_rfa_1p2>;
		vddrfa1p7-supply = <&vreg_pmu_rfa_1p7>;

		max-speed = <3200000>;
	};
};

&sdhc_2 {
	cd-gpios = <&pm8550_gpios 12 GPIO_ACTIVE_LOW>;
	pinctrl-names = "default", "sleep";
	pinctrl-0 = <&sdc2_default &sdc2_card_det_n>;
	pinctrl-1 = <&sdc2_sleep &sdc2_card_det_n>;
	vmmc-supply = <&vreg_l9b_2p9>;
	vqmmc-supply = <&vreg_l8b_1p8>;
	bus-width = <4>;
	no-sdio;
	no-mmc;
	status = "okay";
};

/* X910 downstream uses PCIe0 and GPIO94/96 for the Kiwi v2 WLAN endpoint. */
/*
 * Rear camera flash: two PM8550 flash channels driving one white LED, as the
 * stock gts9wifi camera node (flash-source flash0/flash1, torch0/torch1).  The
 * desktop's flashlight toggle looks for /sys/class/leds/white:flash.
 */
&pm8550_flash {
	status = "okay";

	led-0 {
		function = LED_FUNCTION_FLASH;
		color = <LED_COLOR_ID_WHITE>;
		led-sources = <1>, <2>;
		led-max-microamp = <300000>;
		flash-max-microamp = <1000000>;
		flash-max-timeout-us = <500000>;
	};
};

&pcie0 {
	/*
	 * Stock gts9wifi pcie0 is pinned to Gen2 (qcom,target-link-speed = 2)
	 * for the QCA6490; unconstrained, the link trains at Gen3 x1 and the
	 * endpoint's config space misbehaves (BAR sizing reads back empty).
	 */
	max-link-speed = <2>;
	wake-gpios = <&tlmm 96 GPIO_ACTIVE_HIGH>;
	perst-gpios = <&tlmm 94 GPIO_ACTIVE_LOW>;
	pinctrl-0 = <&pcie0_default_state>;
	pinctrl-names = "default";
	status = "okay";
};

/*
 * Adreno 740 GPU.  gpucc, the GMU and the adreno SMMU are enabled by default in
 * sm8550.dtsi; only the GPU node itself ships disabled.  The zap shader must be
 * signed for this device's TrustZone, so point it at Samsung's stock MDT
 * (a740_zap.mdt + a740_zap.b0N) staged under /lib/firmware/qcom.
 */
&gpu {
	status = "okay";

	zap-shader {
		firmware-name = "qcom/a740_zap.mdt";
	};
};

/*
 * The GMU never binds a driver of its own: the Adreno driver takes over this
 * node's clocks, power domains and registers when the GPU binds.  fw_devlink
 * still waits for it as a consumer, so gcc and gpucc never reached
 * sync_state() and genpd kept every GDSC that was on at boot, the GPU's CX
 * among them, powered for good.  As post-init providers the two links become
 * FWLINK_FLAG_IGNORE ones, which fw_devlink drops without creating a device
 * link (fw_devlink_create_devlink()).  Probe order is unchanged: this device
 * never probes, and the GPU still waits for gpucc through adreno_smmu.
 */
&gmu {
	post-init-providers = <&gcc>, <&gpucc>;
};

/*
 * Mainline's QCE driver has no runtime PM: once bound it holds 393.6 MB/s on
 * its DDR path for good, tagged QCOM_ICC_TAG_ALWAYS, so the vote stays in the
 * sleep set too (drivers/crypto/qce/core.c).  Samsung's qcedev votes only
 * while a client holds /dev/qce open.  Nothing here would use it either: the
 * ARMv8 crypto extensions outrank it (priority 300 against 275).  Left enabled
 * without a driver it kept aggre2 and mc_virt from sync_state(); disabled, it
 * is simply not a consumer.
 */
&crypto {
	status = "disabled";
};

&pcieport0 {
	wifi@0 {
		compatible = "pci17cb,1103";
		reg = <0x10000 0x0 0x0 0x0 0x0>;
		vddrfacmn-supply = <&vreg_pmu_rfa_cmn>;
		vddaon-supply = <&vreg_pmu_aon_0p8>;
		vddwlcx-supply = <&vreg_pmu_wlcx_0p8>;
		vddwlmx-supply = <&vreg_pmu_wlmx_0p8>;
		vddrfa0p8-supply = <&vreg_pmu_rfa_0p8>;
		vddrfa1p2-supply = <&vreg_pmu_rfa_1p2>;
		vddrfa1p8-supply = <&vreg_pmu_rfa_1p7>;
		vddpcie0p9-supply = <&vreg_pmu_pcie_0p9>;
		vddpcie1p8-supply = <&vreg_pmu_pcie_1p8>;
	};
};

&pcie0_phy {
	vdda-phy-supply = <&vreg_l1e_0p88>;
	vdda-pll-supply = <&vreg_l3e_1p2>;
	status = "okay";
};

&sleep_clk {
	clock-frequency = <32764>;
};

/* X910 uses a PTN3222-compatible NXP eUSB2 repeater on I2C6. */
&usb_1_hsphy {
	vdd-supply = <&vreg_l1e_0p88>;
	vdda12-supply = <&vreg_l3e_1p2>;
	phys = <&eusb2_repeater>;
	status = "okay";
};

&usb_1 {
	status = "okay";
};

&usb_1_dwc3_hs {
	remote-endpoint = <&sm5714_hs_in>;
};

&usb_dp_qmpphy {
	vdda-phy-supply = <&vreg_l3e_1p2>;
	vdda-pll-supply = <&vreg_l3f_0p88>;
	status = "okay";
};

&usb_dp_qmpphy_out {
	remote-endpoint = <&ps5169_ss_in>;
};

&mdss_dp0 {
	/*
	 * The ANA38407 needs one platform suspend/resume after a cold boot.
	 * Activating the external DPU encoder before that cycle makes the
	 * platform suspend reset the board.  Keep Type-C negotiation and USB
	 * host mode alive, but replay its out-of-band HPD after the recovery.
	 */
	qcom,defer-hpd-until-first-resume;
	status = "okay";
};

&xo_board {
	clock-frequency = <76800000>;
};

/* ANA38407 AMSA10FA01 native display pipeline. */

/ {
	/*
	 * AMOLED ELVDD (~5.5 V) behind a GPIO load switch (tlmm 202,
	 * enable-active-high); the stock DTS models this as display_panel_avdd.
	 */
	/*
	 * Logic power for the STM32 in Samsung's pogo keyboard: the X710 tree
	 * describes the same active-high switch on TLMM GPIO10 as the Ultra.
	 * Not always-on: the keyboard driver owns the rail.
	 */
	pogo_vddo: pogo-vddo-regulator {
		compatible = "regulator-fixed";
		regulator-name = "pogo_vddo";
		gpio = <&tlmm 10 GPIO_ACTIVE_HIGH>;
		enable-active-high;
		pinctrl-names = "default";
		pinctrl-0 = <&pogo_vddo_en>;
	};

	/*
	 * 1.8 V panel I/O LDO behind GPIO 187: Samsung's gts9wifi r04 tree carries it as
	 * fixed_regulator "panel_ldo_en" and the booting pmOS tree keeps it always on.
	 */
	panel_ldo: regulator-panel-ldo {
		compatible = "regulator-fixed";
		regulator-name = "panel_ldo_en";
		regulator-min-microvolt = <1800000>;
		regulator-max-microvolt = <1800000>;
		gpio = <&tlmm 187 GPIO_ACTIVE_HIGH>;
		enable-active-high;
		regulator-boot-on;
		regulator-always-on;
	};

	display_avdd: regulator-display-avdd {
		compatible = "regulator-fixed";
		regulator-name = "display_panel_avdd";
		regulator-min-microvolt = <5500000>;
		regulator-max-microvolt = <5500000>;
		/* PM8550 GPIO 11 on the 11"; the Ultra drives this rail from TLMM 202. */
		gpio = <&pm8550_gpios 11 GPIO_ACTIVE_HIGH>;
		enable-active-high;
		regulator-boot-on;
	};
};

&mdss {
	status = "okay";
};

&mdss_dsi0 {
	vdda-supply = <&vreg_l3e_1p2>;
	status = "okay";

	panel@0 {
		compatible = "samsung,ana38407-amsa10fa01";
		reg = <0>;

		vddio-supply = <&vreg_l12b_1p8>;
		vdd-supply = <&vreg_l11b_1p2>;
		vci-supply = <&vreg_l13b_3p0>;
		avdd-supply = <&display_avdd>;

		reset-gpios = <&tlmm 125 GPIO_ACTIVE_HIGH>;
		te-gpios = <&tlmm 86 GPIO_ACTIVE_HIGH>;
		/*
		 * samsung,tcon-rdy-gpio of the stock GTS9_ANA38407_AMSA10FA01
		 * node: the DDIC raises it once it is out of reset, and
		 * Samsung's Anapass power sequence sends nothing before that.
		 */
		tcon-rdy-gpios = <&tlmm 88 GPIO_ACTIVE_HIGH>;

		pinctrl-0 = <&sde_te>, <&panel_tcon_rdy>;
		pinctrl-names = "default";

		port {
			panel0_in: endpoint {
				remote-endpoint = <&mdss_dsi0_out>;
			};
		};
	};
};

&mdss_dsi0_out {
	data-lanes = <0 1 2 3>;
	remote-endpoint = <&panel0_in>;
};

&mdss_dsi0_phy {
	vdds-supply = <&vreg_l1e_0p88>;
	/*
	 * Samsung's D-PHY timing table for this glass, TIMING_CTRL_0..13: every
	 * timing node of the stock GTS9_ANA38407_AMSA10FA01 panel carries it
	 * as qcom,mdss-dsi-panel-phy-timings, with t-clk-pre/post 0x2a/0x12, at
	 * its single 1.524 Gbps lane rate.  The PHY replays it whenever the
	 * requested rate is within 1% of that, and computes its own otherwise.
	 */
	qcom,dsi-phy-timings = /bits/ 8 <0x00 0x35 0x0d 0x0d 0x1f 0x27 0x0d
					 0x0d 0x0c 0x02 0x04 0x00 0x2a 0x12>;
	qcom,dsi-phy-timings-bitclk-hz = <1524000000>;
	status = "okay";
};

/*
 * Internal UFS.  The rootfs boots from the microSD; this only exists so pmOS
 * can reach the on-device boot partition and flash new builds over SSH without
 * a TWRP round-trip.  A UFS probe failure does not affect the SD boot.
 */
&ufs_mem_hc {
	reset-gpios = <&tlmm 210 GPIO_ACTIVE_LOW>;
	vcc-supply = <&vreg_l17b_2p5>;
	vcc-max-microamp = <1300000>;
	vccq-supply = <&vreg_l1g_1p2>;
	vccq-max-microamp = <1200000>;
	vdd-hba-supply = <&vreg_l3g_1p2>;
	status = "okay";
};

&ufs_mem_phy {
	vdda-phy-supply = <&vreg_l1e_0p88>;
	vdda-pll-supply = <&vreg_l3e_1p2>;
	status = "okay";
};

/*
 * DMIC pins.  Stock X710 r04 muxes cdc_dmic01, cdc_dmic23 and cdc_dmic45 and
 * leaves cdc_dmic67 (LPI gpio17/18) disabled: the microphones are on DMIC1,
 * DMIC3 and DMIC5 only.  It drives all of these pins at 2 mA, so lower the
 * 8 mA of sm8550.dtsi's dmic01/dmic23 states to match, and describe the third
 * pair, which the SoC file does not.
 */
&lpass_tlmm {
	dmic01-default-state {
		clk-pins {
			drive-strength = <2>;
		};

		data-pins {
			drive-strength = <2>;
		};
	};

	dmic23-default-state {
		clk-pins {
			drive-strength = <2>;
		};

		data-pins {
			drive-strength = <2>;
		};
	};

	dmic45_default: dmic45-default-state {
		clk-pins {
			pins = "gpio12";
			function = "dmic3_clk";
			drive-strength = <2>;
			output-high;
		};

		data-pins {
			pins = "gpio13";
			function = "dmic3_data";
			drive-strength = <2>;
			input-enable;
		};
	};
};

&lpass_vamacro {
	pinctrl-names = "default";
	pinctrl-0 = <&dmic01_default>, <&dmic23_default>, <&dmic45_default>;
	/*
	 * DMIC clock.  The driver divides VA_MACRO_MCLK_FREQ, 9.6 MHz (it runs
	 * the mclk at twice that), so 2.4 MHz is divider 4.  That is the rate
	 * stock drives these microphones at for every capture above 16 kHz:
	 * its TX macro has qcom,tx-dmic-sample-rate = <2400000>, and its VA
	 * macro, set to 600 kHz for voice wake-up, switches to divider 4 in
	 * hw_params above 16 kHz (lpass-cdc-va-macro.c, clk_div_switch).
	 * Without the property the driver falls back to divider 2, 4.8 MHz, a
	 * rate stock never runs these parts at.
	 */
	qcom,dmic-sample-rate = <2400000>;
	/* See vreg_l10b_1p8: the DMIC bias rail Samsung uses for va-vdd-micb. */
	vdd-micb-supply = <&vreg_l10b_1p8>;
	status = "okay";
};

/*
 * ADSP (audio DSP) — step 1 of internal audio.  Uses Samsung's own signed
 * firmware (adsp.mdt + adsp_dtb.mdt + segments, extracted from apnhlos) because
 * the reference qcom/sm8550/adsp.mbn is Qualcomm-signed and rejected by Samsung
 * secure boot.  The sm8550-adsp-pas driver has dtb_pas_id set, so the second
 * firmware-name entry (index 1) is mandatory — without it request_firmware for
 * adsp_dtb.mdt fails and the ADSP never boots.  Both paths carry the qcom/sm8550
 * prefix so the loader looks under /usr/lib/firmware/qcom/sm8550/.
 * The ADSP is not on the boot path (rootfs is on the microSD), so a probe
 * failure does not break booting.  q6/soundwire/codecs/sound come later.
 */
&remoteproc_adsp {
	firmware-name = "qcom/sm8550/adsp.mdt",
			"qcom/sm8550/adsp_dtb.mdt";
	/*
	 * Hub SE3 and SE4 are both enabled on the AP side in GPI-DMA mode for the
	 * SM5440 and MAX77816.  They therefore own their pinctrl states while the
	 * same serial engines remain usable by SSC firmware.  Giving GPIO4/5 to
	 * remoteproc as well makes pinctrl reject the ADSP probe and removes every
	 * sensor.  This is the same measured ownership rule already used by SE3.
	 */
	/delete-property/ pinctrl-names;
	/delete-property/ pinctrl-0;
	/*
	 * Bring-up: drop the LPASS interconnect path.  The upstream node votes
	 * bandwidth over <&lpass_lpicx_noc MASTER_LPASS_PROC ... &mc_virt
	 * SLAVE_EBI1 ...>, but on this tree of_icc_get for that path never
	 * resolves (the LPASS sub-graph does not connect to mc_virt in the
	 * registered icc graph; lpass_ag_noc@7e40000 is disabled upstream), so
	 * the driver stays in -EPROBE_DEFER and never reaches firmware load.
	 * qcom_q6v5_init() treats a NULL path as valid (devm_of_icc_get returns
	 * NULL when the property is absent, and icc_set_bw(NULL,...) is a no-op),
	 * so deleting it lets the ADSP actually attempt PAS auth/boot.  Restore a
	 * real path once the LPASS interconnect graph is fixed.
	 */
	/delete-property/ interconnects;
	status = "okay";
};

/*
 * Speaker I2C bus drive strength.  The four CS35L45 amplifiers sit on the QUPv3
 * I2C master hub SE6 (998000.i2c, Samsung's I2C18) which this board runs at
 * 1 MHz, i.e. Fast-Mode Plus.  Mainline's generic hub_i2c6_data_clk state asks
 * for the weakest TLMM setting, drive-strength = <2>; Samsung's own
 * qupv3_hub_i2c6_{sda,scl}_active states use <8> for the same two pins with the
 * same pull-up and the same mux (their per-line i2chub0_se6_l0/l1 functions are
 * mainline's single i2chub0_se6, func1 on gpio8 and gpio9).
 *
 * With 2 mA the edges cannot meet FM+ timing against four amplifier loads: the
 * GENI controller never completes the first transfer and returns -110 after
 * ~1.0 s, which surfaces as "Timeout waiting for OTP boot" even though the rail
 * (tlmm19) is high and the shared reset (tlmm42) is verifiably released - a
 * gpio/i2c ftrace shows gpio 578 going 0 -> 1 and then a single i2c_write whose
 * i2c_result is ret=-110.  Match Samsung's drive strength; nothing else in the
 * bus configuration differs from stock.
 */
&hub_i2c6_data_clk {
	drive-strength = <8>;
};

/*
 * Cameras.  The SM-X710 has two modules and both are SK hynix HI1337s (stock
 * CamX com.samsung.sensormodule.0_hynix_hi1337, 1_hynix_hi1337_front and
 * 12_hynix_hi1337_front_full), wired exactly like the SM-X910's rear-main and
 * front-main modules (stock gts9wifi overlay: qcom,cam-sensor0, eeprom0,
 * actuator0, eeprom20 and cam-sensor1/12):
 *
 *   rear   CCI0 master 1 @ 0x21, CSIPHY1 x4, MCLK2 (GPIO102), reset GPIO70,
 *          VIO L4B 1.8 V through the GPIO15 switch (RCAM_LDO_EN), VDIG L1C
 *          1.1 V; DW9808 VCM on CCI1 master 0 @ 0x0c behind the same switch.
 *   front  CCI1 master 1 (the AON pair, GPIO208/209) @ 0x20, CSIPHY4 x4,
 *          MCLK4 (GPIO104), reset GPIO117, module LDO GPIO17 (FCAM_LDO_EN),
 *          VIO L4B, VDIG L11B.
 *
 * The register tables the hi1337-gts9u driver writes were decoded from the
 * SM-X910's blobs; the SM-X710 blobs carry the same 1476-entry global table,
 * a rear 4128x3096 mode identical to the X910 rear-main's, and a front
 * 4000x3000 mode (12_..._front_full) identical to the X910 front
 * ultra-wide's.  Hence the "rear" and "front-uw" variants below.
 *
 * Stock votes 1.1 V for the front VDIG on L11B (every gts9wifi overlay entry
 * sets pm_humu_l11 to 1.1 V); this tree holds L11B at 1.2 V for the panel and
 * the sensor driver sets no voltage, so the front module runs its core 0.1 V
 * above stock.
 *
 * Nothing here probes at boot: CAMSS, both CCI controllers, the rear VIO
 * switch and the three I2C devices are disabled.  gts9wifi_camera
 * (drivers/media/i2c/gts9wifi_camera.c) turns the chosen camera(s) on at
 * runtime, on request only; see docs/gts9wifi-cameras.md.  The two LDOs below
 * are only registered: nothing enables them until a camera powers up.
 */
&apps_rsc {
	regulators-0 {
		/* Shared 1.8 V camera I/O rail (Samsung pm_humu_l4). */
		vreg_l4b_1p8: ldo4 {
			regulator-name = "vreg_l4b_1p8";
			regulator-min-microvolt = <1800000>;
			regulator-max-microvolt = <1800000>;
			regulator-initial-mode = <RPMH_REGULATOR_MODE_HPM>;
		};
	};

	/* PM8550VS-C L1: the rear module's 1.1 V digital rail (pm_v6c_l1). */
	regulators-1 {
		compatible = "qcom,pm8550vs-rpmh-regulators";
		qcom,pmic-id = "c";

		vreg_l1c_1p1: ldo1 {
			regulator-name = "vreg_l1c_1p1";
			/* PM8550VS NLDO steps are 8 mV; 1.104 V is closest to stock 1.1 V. */
			regulator-min-microvolt = <1104000>;
			regulator-max-microvolt = <1104000>;
			regulator-initial-mode = <RPMH_REGULATOR_MODE_HPM>;
		};
	};
};

/ {
	/*
	 * GPIO15 (RCAM_LDO_EN) switches the rear module rail shared by the
	 * HI1337's VIO and the DW9808's VCC.  A regulator lets both media
	 * entities hold it without fighting over the GPIO.
	 */
	rear_cam_vio: rear-camera-vio-regulator {
		compatible = "regulator-fixed";
		regulator-name = "rear_cam_vio";
		regulator-min-microvolt = <1800000>;
		regulator-max-microvolt = <1800000>;
		vin-supply = <&vreg_l4b_1p8>;
		gpio = <&tlmm 15 GPIO_ACTIVE_HIGH>;
		enable-active-high;
		status = "disabled";
	};
};

&camss {
	vdda-phy-supply = <&vreg_l1e_0p88>;
	vdda-pll-supply = <&vreg_l3e_1p2>;
	/* Enabled at runtime by gts9wifi_camera. */
	status = "disabled";

	ports {
		port@1 {
			csiphy1_gts9_rear_ep: endpoint {
				clock-lanes = <4>;
				data-lanes = <0 1 2 3>;
				remote-endpoint = <&gts9_rear_cam_ep>;
			};
		};

		port@4 {
			csiphy4_gts9_front_ep: endpoint {
				clock-lanes = <4>;
				data-lanes = <0 1 2 3>;
				remote-endpoint = <&gts9_front_cam_ep>;
			};
		};
	};
};

&cci0 {
	/* Enabled at runtime by gts9wifi_camera. */
	status = "disabled";
};

&cci0_i2c1 {
	gts9_rear_cam: camera@21 {
		compatible = "hynix,hi1337-gts9u-rear";
		reg = <0x21>;
		clocks = <&camcc CAM_CC_MCLK2_CLK>;
		assigned-clocks = <&camcc CAM_CC_MCLK2_CLK>;
		assigned-clock-rates = <19200000>;
		vddio-supply = <&rear_cam_vio>;
		vdig-supply = <&vreg_l1c_1p1>;
		reset-gpios = <&tlmm 70 GPIO_ACTIVE_LOW>;
		pinctrl-0 = <&cam2_default>;
		pinctrl-1 = <&cam2_sleep>;
		pinctrl-names = "default", "sleep";
		/* Stock sensor-position roll 90, yaw 180. */
		orientation = <1>;
		rotation = <90>;
		lens-focus = <&gts9_rear_focus>;
		status = "disabled";

		port {
			gts9_rear_cam_ep: endpoint {
				clock-lanes = <4>;
				data-lanes = <0 1 2 3>;
				link-frequencies = /bits/ 64 <360200000>;
				remote-endpoint = <&csiphy1_gts9_rear_ep>;
			};
		};
	};
};

&cci1 {
	pinctrl-0 = <&cci1_0_default &cci1_1_default>;
	pinctrl-1 = <&cci1_0_sleep &cci1_1_sleep>;
	/* Enabled at runtime by gts9wifi_camera. */
	status = "disabled";

	cci1_i2c1: i2c-bus@1 {
		reg = <1>;
		clock-frequency = <1000000>;
		#address-cells = <1>;
		#size-cells = <0>;
	};
};

&cci1_i2c0 {
	/* Stock actuator0: slave-addr 0x18 (8-bit), CCI1 master 0. */
	gts9_rear_focus: lens@c {
		compatible = "dongwoon,dw9808-vcm";
		reg = <0x0c>;
		vcc-supply = <&rear_cam_vio>;
		status = "disabled";
	};
};

&cci1_i2c1 {
	gts9_front_cam: camera@20 {
		/* The 4000x3000 table of the X910 front ultra-wide; see above. */
		compatible = "hynix,hi1337-gts9u-front-uw";
		/* Stock slave-addr 0x40 is the 8-bit form of 0x20. */
		reg = <0x20>;
		clocks = <&camcc CAM_CC_MCLK4_CLK>;
		assigned-clocks = <&camcc CAM_CC_MCLK4_CLK>;
		assigned-clock-rates = <19200000>;
		vddio-supply = <&vreg_l4b_1p8>;
		vdig-supply = <&vreg_l11b_1p2>;
		enable-gpios = <&tlmm 17 GPIO_ACTIVE_HIGH>;
		reset-gpios = <&tlmm 117 GPIO_ACTIVE_LOW>;
		pinctrl-0 = <&cam4_default>;
		pinctrl-1 = <&cam4_sleep>;
		pinctrl-names = "default", "sleep";
		/* Stock sensor-position roll 270, yaw 0. */
		orientation = <0>;
		rotation = <270>;
		status = "disabled";

		port {
			gts9_front_cam_ep: endpoint {
				clock-lanes = <4>;
				data-lanes = <0 1 2 3>;
				link-frequencies = /bits/ 64 <360200000>;
				remote-endpoint = <&csiphy4_gts9_front_ep>;
			};
		};
	};
};

&tlmm {
	/* CCI1 master 1 is Samsung's AON CCI pair (stock cci_aon_i2c_*). */
	cci1_1_default: cci1-1-default-state {
		pins = "gpio208", "gpio209";
		function = "aon_cci";
		drive-strength = <4>;
		bias-pull-up;
	};

	cci1_1_sleep: cci1-1-sleep-state {
		pins = "gpio208", "gpio209";
		function = "aon_cci";
		drive-strength = <4>;
		bias-disable;
		input-enable;
	};
};
